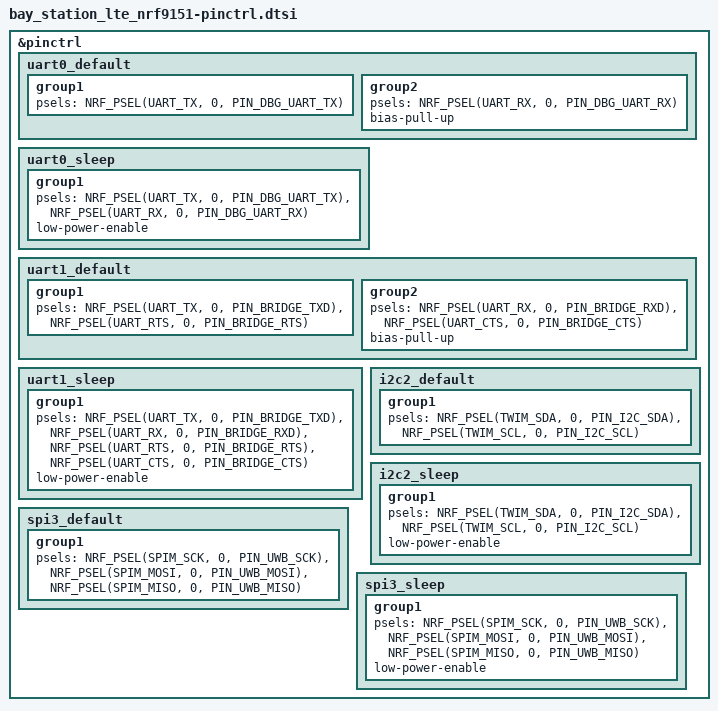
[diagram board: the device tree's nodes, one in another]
/*
 * Pin control for the nRF9151 side. Pin NUMBERS come only from
 * bay_station_lte_pins.h; this file only says which net goes to which
 * peripheral signal (numbers from bay-station/connectivity_notes.md s2).
 *
 * nRF91 serial peripherals can be routed to any GPIO (PSEL), so instance
 * choice does not constrain the pin map -- but UARTE/SPIM/TWIM share
 * instances 0-3, and this board uses all four (see bay-station/README.md
 * "Peripheral instances"). There is no spare serial instance.
 */
#include "bay_station_lte_pins.h"

&pinctrl {
	/* UARTE0: DBG_UART_TX / DBG_UART_RX -- shell + log */
	uart0_default: uart0_default {
		group1 {
			psels = <NRF_PSEL(UART_TX, 0, PIN_DBG_UART_TX)>;
		};
		group2 {
			psels = <NRF_PSEL(UART_RX, 0, PIN_DBG_UART_RX)>;
			bias-pull-up;
		};
	};
	uart0_sleep: uart0_sleep {
		group1 {
			psels = <NRF_PSEL(UART_TX, 0, PIN_DBG_UART_TX)>,
				<NRF_PSEL(UART_RX, 0, PIN_DBG_UART_RX)>;
			low-power-enable;
		};
	};

	/* UARTE1: BRIDGE_TXD / BRIDGE_RXD / BRIDGE_RTS / BRIDGE_CTS -> BT840 */
	uart1_default: uart1_default {
		group1 {
			psels = <NRF_PSEL(UART_TX, 0, PIN_BRIDGE_TXD)>,
				<NRF_PSEL(UART_RTS, 0, PIN_BRIDGE_RTS)>;
		};
		group2 {
			psels = <NRF_PSEL(UART_RX, 0, PIN_BRIDGE_RXD)>,
				<NRF_PSEL(UART_CTS, 0, PIN_BRIDGE_CTS)>;
			bias-pull-up;
		};
	};
	uart1_sleep: uart1_sleep {
		group1 {
			psels = <NRF_PSEL(UART_TX, 0, PIN_BRIDGE_TXD)>,
				<NRF_PSEL(UART_RX, 0, PIN_BRIDGE_RXD)>,
				<NRF_PSEL(UART_RTS, 0, PIN_BRIDGE_RTS)>,
				<NRF_PSEL(UART_CTS, 0, PIN_BRIDGE_CTS)>;
			low-power-enable;
		};
	};

	/* TWIM2: I2C_SCL / I2C_SDA (pull-ups R37/R38 are on the board) */
	i2c2_default: i2c2_default {
		group1 {
			psels = <NRF_PSEL(TWIM_SDA, 0, PIN_I2C_SDA)>,
				<NRF_PSEL(TWIM_SCL, 0, PIN_I2C_SCL)>;
		};
	};
	i2c2_sleep: i2c2_sleep {
		group1 {
			psels = <NRF_PSEL(TWIM_SDA, 0, PIN_I2C_SDA)>,
				<NRF_PSEL(TWIM_SCL, 0, PIN_I2C_SCL)>;
			low-power-enable;
		};
	};

	/* SPIM3: UWB_SCK / UWB_MOSI / UWB_MISO, shared by all four DW3210 */
	spi3_default: spi3_default {
		group1 {
			psels = <NRF_PSEL(SPIM_SCK, 0, PIN_UWB_SCK)>,
				<NRF_PSEL(SPIM_MOSI, 0, PIN_UWB_MOSI)>,
				<NRF_PSEL(SPIM_MISO, 0, PIN_UWB_MISO)>;
			/* TODO(fw-m3): high-drive (nordic,drive-mode) on SCK/MOSI if the
			 * shared 4-load bus shows slow edges on the scope. */
		};
	};
	spi3_sleep: spi3_sleep {
		group1 {
			psels = <NRF_PSEL(SPIM_SCK, 0, PIN_UWB_SCK)>,
				<NRF_PSEL(SPIM_MOSI, 0, PIN_UWB_MOSI)>,
				<NRF_PSEL(SPIM_MISO, 0, PIN_UWB_MISO)>;
			low-power-enable;
		};
	};
};
